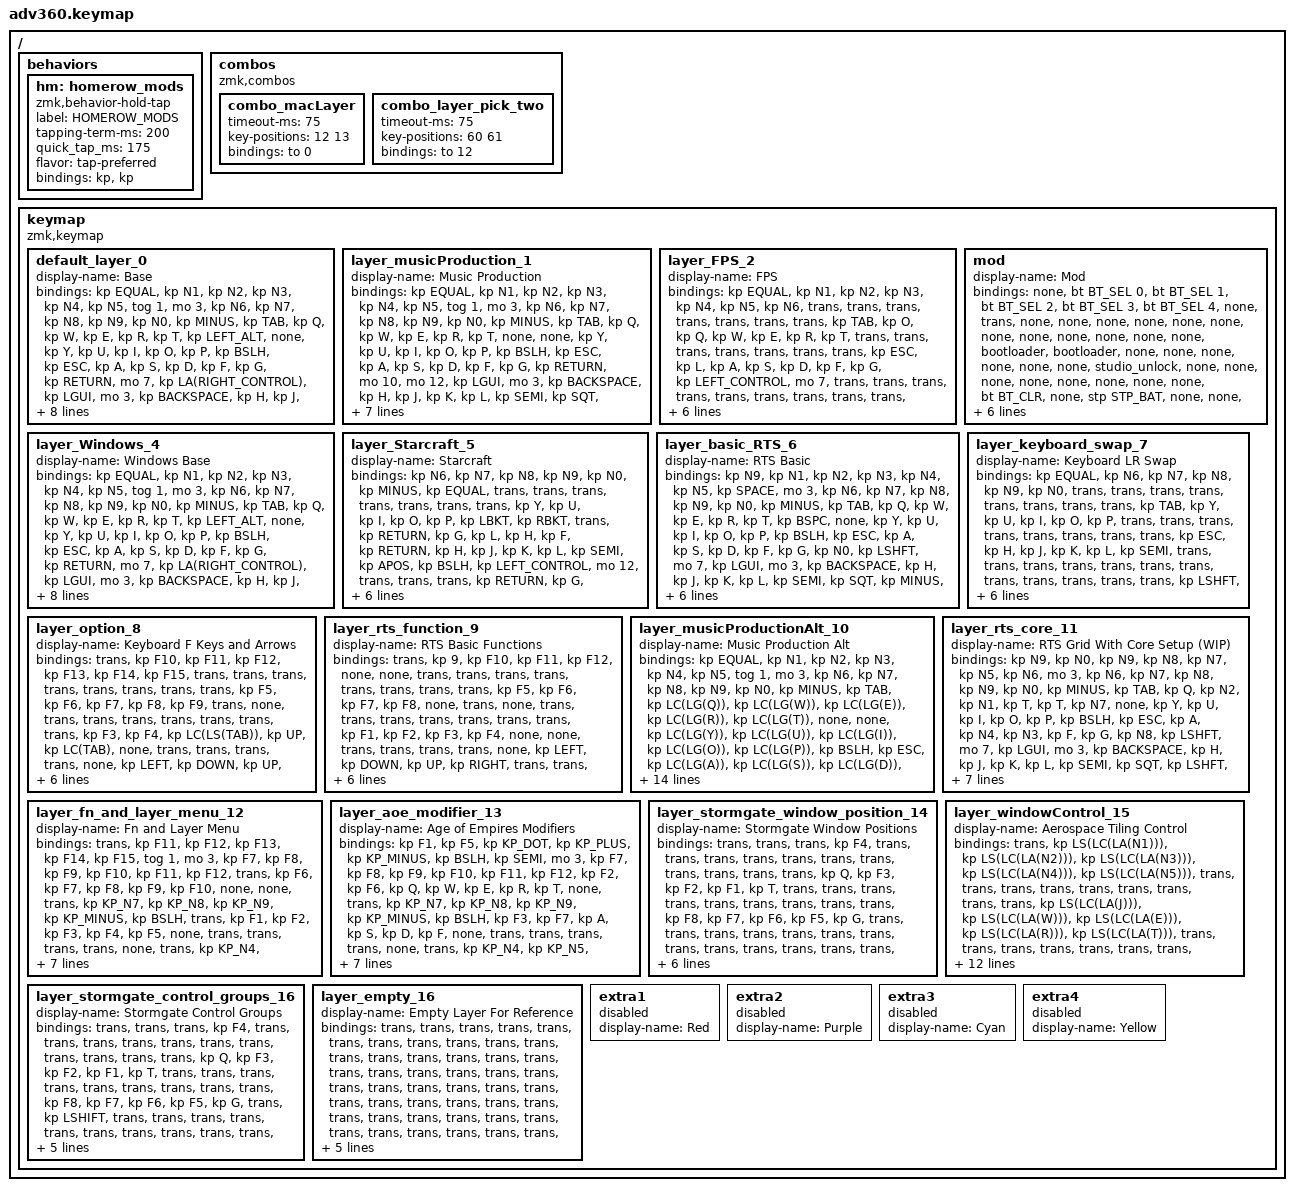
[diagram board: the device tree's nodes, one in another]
#include <behaviors.dtsi>
#include <dt-bindings/zmk/keys.h>
#include <dt-bindings/zmk/bt.h>
#include <dt-bindings/zmk/rgb.h>
#include <dt-bindings/zmk/stp.h>
#include <dt-bindings/zmk/backlight.h>
#include <dt-bindings/zmk/pointing.h>

#define HYPERNOSHIFT LC(LA(LGUI))
#define SEMIHYPER LC(LGUI)

/ {
    behaviors {
      #include "macros.dtsi"
      #include "version.dtsi"

      hm: homerow_mods {
          compatible = "zmk,behavior-hold-tap";
          label = "HOMEROW_MODS";
          #binding-cells = <2>;
          tapping-term-ms = <200>;
          quick_tap_ms = <175>;
          flavor = "tap-preferred";
          bindings = <&kp>, <&kp>;
      };
    };

  combos {
      compatible = "zmk,combos";
      combo_macLayer {
          timeout-ms = <75>;
          key-positions = <12 13>;
          bindings = <&to 0>;
      };
      combo_layer_pick_two {
          timeout-ms = <75>;
          key-positions = <60 61>;
          bindings = <&to 12>;
      };
  };

  keymap {
    compatible = "zmk,keymap";

    default_layer_0 {
      display-name = "Base";
      bindings = <
        &kp EQUAL          &kp N1        &kp N2         &kp N3        &kp N4      &kp N5       &tog 1                                                                                      &mo 3           &kp N6   &kp N7     &kp N8      &kp N9        &kp N0      &kp MINUS
        &kp TAB            &kp Q         &kp W          &kp E         &kp R       &kp T        &kp LEFT_ALT                                                                                &none           &kp Y    &kp U      &kp I       &kp O         &kp P       &kp BSLH
        &kp ESC            &kp A         &kp S          &kp D         &kp F       &kp G        &kp RETURN        &mo 7      &kp LA(RIGHT_CONTROL)            &kp LGUI       &mo 3          &kp BACKSPACE   &kp H    &kp J      &kp K       &kp L         &kp SEMI    &kp SQT
        &kp LSHFT          &kp Z         &kp X          &kp C         &kp V       &kp B                                     &kp LSHFT                        &kp PG_UP                                     &kp N    &kp M      &kp COMMA   &kp DOT       &kp FSLH    &kp RSHFT
        &kp LEFT_ALT       &kp GRAVE     &kp LA(LG(I))  &kp BSPC      &kp SPACE                &kp RIGHT_CONTROL &kp LCMD   &mo 8                            &kp LEFT_ALT   &kp ENTER      &kp SPACE                &kp UP     &kp DOWN    &kp LBKT      &kp RBKT    &sl 4
      >;
    };
    layer_musicProduction_1 {
      display-name = "Music Production";
      bindings = <
        &kp EQUAL          &kp N1        &kp N2         &kp N3        &kp N4      &kp N5             &tog 1                                                                                &mo 3            &kp N6   &kp N7     &kp N8      &kp N9        &kp N0      &kp MINUS
        &kp TAB            &kp Q         &kp W          &kp E         &kp R       &kp T              &none                                                                                 &none            &kp Y    &kp U      &kp I       &kp O         &kp P       &kp BSLH
        &kp ESC            &kp A         &kp S          &kp D         &kp F       &kp G              &kp RETURN          &mo 10       &mo 12                  &kp LGUI       &mo 3         &kp BACKSPACE    &kp H    &kp J      &kp K       &kp L         &kp SEMI    &kp SQT
        &kp LSHFT          &kp Z         &kp X          &kp C         &kp V       &kp B                                  &kp LSHFT               &kp PG_UP                                     &kp N    &kp M      &kp COMMA   &kp DOT       &kp FSLH    &kp RSHFT
        &kp LEFT_ALT       &kp GRAVE     &kp LA(LG(I))  &kp BSPC      &kp BACKSPACE                  &kp RIGHT_CONTROL   &kp LCMD     &mo 8                   &kp LEFT_ALT   &kp ENTER      &kp SPACE                &kp UP     &kp DOWN    &kp LBKT      &kp RBKT    &sl 4
      >;
    };

    layer_FPS_2 {
      display-name = "FPS";
      bindings = <
        &kp EQUAL          &kp N1             &kp N2        &kp N3        &kp N4        &kp N5   &kp N6                                                                        &trans  &trans  &trans  &trans  &trans  &trans  &trans
        &kp TAB            &kp O              &kp Q         &kp W         &kp E         &kp R    &kp T                                                                         &trans  &trans  &trans  &trans  &trans  &trans  &trans
        &kp ESC            &kp L              &kp A         &kp S         &kp D         &kp F    &kp G      &kp LEFT_CONTROL      &mo 7                        &trans  &trans  &trans  &trans  &trans  &trans  &trans  &trans  &trans
        &kp DOT            &kp Z              &kp X         &kp C         &kp V         &kp B                                     &kp SEMI                                     &trans  &trans  &trans  &trans  &trans  &trans  &trans
        &kp LEFT_ALT       &kp GRAV           &kp FSLH      &kp ENTER     &kp LEFT_ALT           &kp LSHIFT &kp SPACE             &mo 12                       &trans  &trans  &trans          &trans  &trans  &trans  &trans  &trans
      >;
    };

    mod {
      display-name = "Mod";
      bindings = <
        &none &bt BT_SEL 0 &bt BT_SEL 1 &bt BT_SEL 2 &bt BT_SEL 3 &bt BT_SEL 4 &none                                                                     &trans                 &none        &none        &none        &none &none &none
        &none &none        &none        &none        &none        &none        &bootloader                                                               &bootloader            &none        &none        &none        &none &none &none
        &studio_unlock &none        &none        &none        &none        &none        &none                   &none &none &bt BT_CLR &none                      &stp STP_BAT &none        &none        &none        &none &none &none
        &none &none        &none        &none        &macro_ver   &none                                      &none &none                                                        &none        &none        &none        &none &none &none
        &none &none        &none        &none        &none                                       &none &none &none &none      &bl BL_TOG &rgb_ug RGB_TOG                                     &bl BL_INC   &bl BL_DEC   &none &none &none
      >;
    };

    layer_Windows_4 {
      display-name = "Windows Base";
      bindings = <
        &kp EQUAL          &kp N1        &kp N2         &kp N3        &kp N4      &kp N5       &tog 1                                                                                            &mo 3           &kp N6   &kp N7     &kp N8      &kp N9        &kp N0      &kp MINUS
        &kp TAB            &kp Q         &kp W          &kp E         &kp R       &kp T        &kp LEFT_ALT                                                                                      &none           &kp Y    &kp U      &kp I       &kp O         &kp P       &kp BSLH
        &kp ESC            &kp A         &kp S          &kp D         &kp F       &kp G        &kp RETURN        &mo 7      &kp LA(RIGHT_CONTROL)                  &kp LGUI       &mo 3          &kp BACKSPACE   &kp H    &kp J      &kp K       &kp L         &kp SEMI    &kp SQT
        &kp LSHFT          &kp Z         &kp X          &kp C         &kp V       &kp B                                     &kp LSHFT                              &kp PG_UP                                     &kp N    &kp M      &kp COMMA   &kp DOT       &kp FSLH    &kp RSHFT
        &kp LCMD           &kp GRAVE     &kp LS(LC(I))  &kp BSPC      &kp SPACE                &kp LEFT_ALT      &kp LEFT_CONTROL   &mo 8                                  &kp LEFT_ALT   &kp ENTER      &kp SPACE                &kp UP     &kp DOWN    &kp LBKT      &kp RBKT    &sl 4
        >;
    };

    layer_Starcraft_5 {
      display-name = "Starcraft";
      bindings = <
        &kp N6   &kp N7     &kp N8     &kp N9   &kp N0    &kp MINUS    &kp EQUAL                                                              &trans       &trans       &trans   &trans   &trans  &trans  &trans
        &kp Y    &kp U      &kp I      &kp O    &kp P     &kp LBKT     &kp RBKT                                                               &trans       &kp RETURN   &kp G    &kp L    &kp H   &kp F   &kp RETURN
        &kp H    &kp J      &kp K      &kp L    &kp SEMI  &kp APOS     &kp BSLH    &kp LEFT_CONTROL  &mo 12                   &trans  &trans  &trans       &kp RETURN   &kp G    &kp ESC  &kp W   &trans  &trans   
        &kp N    &kp M      &kp COMMA  &kp DOT  &kp FSLH  &kp G                                      &trans                   &trans                       &trans       &trans   &trans   &trans  &trans  &trans
        &kp TAB  &kp GRAVE  &kp T      &kp V    &kp B                  &kp RSHFT   &kp LEFT_ALT      &trans                   &trans  &trans  &trans                    &trans   &trans   &trans  &trans  &to 0
      >;
    };

    layer_basic_RTS_6 {
      display-name = "RTS Basic";
      bindings = <
        &kp N9             &kp N1        &kp N2         &kp N3        &kp N4      &kp N5       &kp SPACE                                                                                         &mo 3           &kp N6   &kp N7     &kp N8      &kp N9        &kp N0      &kp MINUS
        &kp TAB            &kp Q         &kp W          &kp E         &kp R       &kp T        &kp BSPC                                                                                          &none           &kp Y    &kp U      &kp I       &kp O         &kp P       &kp BSLH
        &kp ESC            &kp A         &kp S          &kp D         &kp F       &kp G        &kp N0            &kp LSHFT  &mo 7                                  &kp LGUI       &mo 3          &kp BACKSPACE   &kp H    &kp J      &kp K       &kp L         &kp SEMI    &kp SQT
        &kp MINUS          &kp Z         &kp X          &kp C         &kp V       &kp B                                     &kp SPACE                              &kp PG_UP                                     &kp N    &kp M      &kp COMMA   &kp DOT       &kp FSLH    &kp RSHFT
        &kp BSLH           &kp GRAVE     &kp N6         &kp N7        &kp N8               &kp LEFT_ALT      &kp LEFT_CONTROL   &mo 9                          &kp LEFT_ALT   &kp ENTER      &kp SPACE                &kp UP     &kp DOWN    &kp LBKT      &kp RBKT    &sl 4
      >;
    };
    
    layer_keyboard_swap_7 {
      display-name = "Keyboard LR Swap";
      bindings = <
        &kp EQUAL    &kp N6   &kp N7     &kp N8      &kp N9        &kp N0      &trans                                                                  &trans  &trans  &trans  &trans  &trans  &trans  &trans
        &kp TAB      &kp Y    &kp U      &kp I       &kp O         &kp P       &trans                                                                  &trans  &trans  &trans  &trans  &trans  &trans  &trans
        &kp ESC      &kp H    &kp J      &kp K       &kp L         &kp SEMI    &trans            &trans    &trans                      &trans  &trans  &trans  &trans  &trans  &trans  &trans  &trans  &trans
        &kp LSHFT    &kp N    &kp M      &kp COMMA   &kp DOT       &kp FSLH                                &kp LSHFT                   &trans                  &trans  &trans  &trans  &trans  &trans  &trans
        &kp LEFT_ALT &none    &none      &none       &none                     &kp RIGHT_CONTROL &kp LCMD  &trans                      &trans  &trans  &trans          &trans  &trans  &trans  &trans  &trans
      >;
    };

    layer_option_8 {
      display-name = "Keyboard F Keys and Arrows";
      bindings = <
        &trans       &kp F10    &kp F11      &kp F12                &kp F13      &kp F14                &kp F15                                                                   &trans        &trans        &trans       &trans         &trans         &trans           &trans
        &trans       &kp F5     &kp F6       &kp F7                 &kp F8       &kp F9                 &trans                                                                    &none         &trans        &trans       &trans         &trans         &trans           &trans
        &trans       &kp F3     &kp F4       &kp LC(LS(TAB))        &kp UP       &kp LC(TAB)            &none      &trans     &trans                       &trans     &trans      &none         &kp LEFT      &kp DOWN     &kp UP         &kp RIGHT      &trans           &trans
        &trans       &kp F1     &kp F2       &kp LEFT               &kp DOWN     &kp RIGHT                                    &mo 12                       &trans                               &trans        &trans       &trans         &trans         &trans           &trans
        &mo 12        &trans     &trans       &kp LEFT_ALT          &mo 9                               &trans     &trans     &trans                       &trans     &trans      &trans                   &trans       &trans         &trans         &trans           &mo 12
      >;
    };

    layer_rts_function_9 {
      display-name = "RTS Basic Functions";
      bindings = <
        &trans       &kp 9      &kp F10      &kp F11                &kp F12      &none                  &none                                                                                       &trans        &trans        &trans       &trans         &trans         &trans           &trans
        &trans       &kp F5     &kp F6       &kp F7                 &kp F8       &none                  &trans                                                                                      &none         &trans        &trans       &trans         &trans         &trans           &trans
        &trans       &kp F1     &kp F2       &kp F3                 &kp F4       &none                  &none             &trans                &trans                       &trans     &trans      &none         &kp LEFT      &kp DOWN     &kp UP         &kp RIGHT      &trans           &trans
        &trans       &none      &none        &none                  &none        &none                                                          &kp LSHFT                    &trans                               &trans        &trans       &trans         &trans         &trans           &trans
        &none        &trans     &trans       &none                  &none                               &kp LEFT_ALT      &kp LEFT_CONTROL      &trans                       &trans     &trans      &trans                      &trans       &trans         &trans         &trans           &mo 12
        >;
    };

    layer_musicProductionAlt_10 {
      display-name = "Music Production Alt";
      bindings = <
        &kp EQUAL          &kp N1                  &kp N2                  &kp N3                  &kp N4                     &kp N5           &tog 1                                                                                             &mo 3           &kp N6            &kp N7              &kp N8               &kp N9          &kp N0             &kp MINUS
        &kp TAB            &kp LC(LG(Q))           &kp LC(LG(W))           &kp LC(LG(E))           &kp LC(LG(R))              &kp LC(LG(T))    &none                                                                                              &none           &kp LC(LG(Y))     &kp LC(LG(U))       &kp LC(LG(I))        &kp LC(LG(O))   &kp LC(LG(P))      &kp BSLH
        &kp ESC            &kp LC(LG(A))           &kp LC(LG(S))           &kp LC(LG(D))           &kp LC(LG(F))              &kp LC(LG(G))    &kp RETURN  &kp SEMIHYPER      &mo 12                                &kp LGUI       &mo 3          &kp BACKSPACE   &kp LC(LG(H))     &kp LC(LG(J))       &kp LC(LG(K))        &kp LC(LG(L))   &kp SEMI           &kp SQT
        &kp LSHFT          &kp LS(LC(LA(LG(Z))))   &kp LS(LC(LA(LG(X))))   &kp LS(LC(LA(LG(C))))   &kp LS(LC(LA(LG(V))))      &kp LC(LG(B))                                   &kp HYPERNOSHIFT                      &kp PG_UP                                     &kp LC(LG(N))     &kp LC(LG(M))       &kp COMMA            &kp DOT         &kp FSLH           &kp RSHFT
        &kp RIGHT_CONTROL  &kp GRAVE               &kp LA(LG(I))           &kp LEFT_ALT            &kp LC(LG(BACKSPACE))                       &kp SPACE   &kp LCMD           &mo 8                                 &kp LEFT_ALT   &kp ENTER      &kp SPACE                         &kp UP              &kp DOWN             &kp LBKT        &kp RBKT           &sl 4
      >;
    };

    layer_rts_core_11 {
      display-name = "RTS Grid With Core Setup (WIP)";
      bindings = <
        &kp N9             &kp N0        &kp N9         &kp N8        &kp N7      &kp N5       &kp N6                                                                                          &mo 3           &kp N6   &kp N7     &kp N8      &kp N9        &kp N0      &kp MINUS
        &kp TAB            &kp Q         &kp N2         &kp N1        &kp T       &kp T        &kp N7                                                                                          &none           &kp Y    &kp U      &kp I       &kp O         &kp P       &kp BSLH
        &kp ESC            &kp A         &kp N4         &kp N3        &kp F       &kp G        &kp N8          &kp LSHFT          &mo 7                          &kp LGUI       &mo 3          &kp BACKSPACE   &kp H    &kp J      &kp K       &kp L         &kp SEMI    &kp SQT
        &kp LSHFT          &kp Z         &kp N6         &kp N5        &kp V       &kp B                                           &kp LSHFT                      &kp PG_UP                                     &kp N    &kp M      &kp COMMA   &kp DOT       &kp FSLH    &kp RSHFT
        &kp LCMD           &kp GRAVE     &kp N0         &kp BSPC      &kp SPACE                &kp LEFT_ALT    &kp LEFT_CONTROL   &mo 9                          &kp LEFT_ALT   &kp ENTER      &kp SPACE                &kp UP     &kp DOWN    &kp LBKT      &kp RBKT    &sl 4
      >;
    };

    layer_fn_and_layer_menu_12 {
      display-name = "Fn and Layer Menu";
      bindings = <
        &trans  &kp F11  &kp F12  &kp F13  &kp F14  &kp F15            &tog 1                                                   &mo 3   &kp F7  &kp F8        &kp F9         &kp F10         &kp F11        &kp F12
        &trans  &kp F6   &kp F7   &kp F8   &kp F9   &kp F10            &none                                                    &none   &trans  &kp KP_N7     &kp KP_N8      &kp KP_N9       &kp KP_MINUS   &kp BSLH
        &trans  &kp F1   &kp F2   &kp F3   &kp F4   &kp F5             &none   &trans  &trans                   &trans  &trans  &none   &trans  &kp KP_N4     &kp KP_N5      &kp KP_N6       &kp KP_PLUS    &kp SQT
        &trans  &to 0    &to 4    &to 2    &to 5    &to 1                              &trans                   &trans                  &trans  &kp KP_N1     &kp KP_N2      &kp KP_N3       &kp KP_ENTER   &kp RSHFT
        &trans  &to 6    &to 11   &trans   &trans                      &trans  &trans  &trans                   &trans  &trans  &trans          &kp KP_N0     &kp KP_N0      &kp KP_DOT      &kp RBKT       &trans
      >;
    };

    layer_aoe_modifier_13 {
      display-name = "Age of Empires Modifiers";
      bindings = <
        &kp F1   &kp F5   &kp KP_DOT   &kp KP_PLUS   &kp KP_MINUS   &kp BSLH   &kp SEMI                                                 &mo 3   &kp F7  &kp F8        &kp F9         &kp F10         &kp F11        &kp F12
        &kp F2   &kp F6   &kp Q        &kp W         &kp E          &kp R      &kp T                                                    &none   &trans  &kp KP_N7     &kp KP_N8      &kp KP_N9       &kp KP_MINUS   &kp BSLH
        &kp F3   &kp F7   &kp A        &kp S         &kp D          &kp F      &none   &trans  &trans                   &trans  &trans  &none   &trans  &kp KP_N4     &kp KP_N5      &kp KP_N6       &kp KP_PLUS    &kp SQT
        &kp F4   &kp F8   &kp Z        &kp X         &kp C          &kp V                      &trans                   &trans                  &trans  &kp KP_N1     &kp KP_N2      &kp KP_N3       &kp KP_ENTER   &kp RSHFT
        &kp F5   &kp F9   &kp Z        &kp X         &kp C                     &trans  &trans  &trans                   &trans  &trans  &trans          &kp KP_N0     &kp KP_N0      &kp KP_DOT      &kp RBKT       &trans
      >;
    };

    layer_stormgate_window_position_14 {
      display-name = "Stormgate Window Positions";
      bindings = <
        &trans  &trans        &trans         &kp F4        &trans      &trans          &trans                                                      &trans  &trans  &trans  &trans  &trans  &trans  &trans
        &trans  &kp Q         &kp F3         &kp F2        &kp F1      &kp T           &trans                                                      &trans  &trans  &trans  &trans  &trans  &trans  &trans
        &trans  &kp F8        &kp F7         &kp F6        &kp F5      &kp G           &trans  &trans  &trans                      &trans  &trans  &trans  &trans  &trans  &trans  &trans  &trans  &trans
        &trans  &kp Z         &kp X          &kp C         &kp V       &kp B                           &kp LEFT_CONTROL            &trans                  &trans  &trans  &trans  &trans  &trans  &trans
        &trans  &trans        &trans         &trans        &trans                      &trans  &trans  &trans                      &trans  &trans  &trans          &trans  &trans  &trans  &trans  &trans
      >;
    };

    layer_windowControl_15 {
      display-name = "Aerospace Tiling Control";
      bindings = <
        &trans  &kp LS(LC(LA(N1)))  &kp LS(LC(LA(N2)))  &kp LS(LC(LA(N3)))  &kp LS(LC(LA(N4)))  &kp LS(LC(LA(N5)))  &trans                                                   &trans  &trans  &trans  &trans  &trans  &trans  &trans
        &trans  &kp LS(LC(LA(J)))   &kp LS(LC(LA(W)))   &kp LS(LC(LA(E)))   &kp LS(LC(LA(R)))   &kp LS(LC(LA(T)))   &trans                                                   &trans  &trans  &trans  &trans  &trans  &trans  &trans
        &trans  &kp LS(LC(LA(A)))   &kp LS(LC(LA(S)))   &kp LS(LC(LA(D)))   &kp LS(LC(LA(F)))   &kp LS(LC(LA(G)))   &trans  &trans  &trans                   &trans  &trans  &trans  &trans  &trans  &trans  &trans  &trans  &trans
        &trans  &kp LS(LC(LA(Z)))   &kp LS(LC(LA(X)))   &kp LS(LC(LA(C)))   &kp LS(LC(LA(V)))   &kp LS(LC(LA(B)))                   &trans                   &trans                  &trans  &trans  &trans  &trans  &trans  &trans
        &trans  &trans              &trans              &trans              &trans                                  &trans  &trans  &trans                   &trans  &trans  &trans          &trans  &trans  &trans  &trans  &trans
      >;
    };

    layer_stormgate_control_groups_16 {
      display-name = "Stormgate Control Groups";
      bindings = <
        &trans  &trans        &trans         &kp F4        &trans      &trans          &trans                                                     &trans  &trans  &trans  &trans  &trans  &trans  &trans
        &trans  &kp Q         &kp F3         &kp F2        &kp F1      &kp T           &trans                                                     &trans  &trans  &trans  &trans  &trans  &trans  &trans
        &trans  &kp F8        &kp F7         &kp F6        &kp F5      &kp G           &trans  &kp LSHIFT  &trans                 &trans  &trans  &trans  &trans  &trans  &trans  &trans  &trans  &trans
        &trans  &kp Z         &kp X          &kp C         &kp V       &kp B                               &trans                 &trans                  &trans  &trans  &trans  &trans  &trans  &trans
        &trans  &trans        &trans         &trans        &trans                      &trans  &trans  &trans                     &trans  &trans  &trans          &trans  &trans  &trans  &trans  &trans
      >;
    };
    layer_empty_16 {
      display-name = "Empty Layer For Reference";
      bindings = <
        &trans  &trans  &trans  &trans  &trans  &trans            &trans                                                     &trans  &trans  &trans  &trans  &trans  &trans  &trans
        &trans  &trans  &trans  &trans  &trans  &trans            &trans                                                     &trans  &trans  &trans  &trans  &trans  &trans  &trans
        &trans  &trans  &trans  &trans  &trans  &trans            &trans  &trans  &trans                     &trans  &trans  &trans  &trans  &trans  &trans  &trans  &trans  &trans
        &trans  &trans  &trans  &trans  &trans  &trans                            &trans                     &trans                  &trans  &trans  &trans  &trans  &trans  &trans
        &trans  &trans  &trans  &trans  &trans                    &trans  &trans  &trans                     &trans  &trans  &trans          &trans  &trans  &trans  &trans  &trans
      >;
    };
    extra1 { 
      display-name = "Red";    
      status = "reserved";
    };

    extra2 { 
      display-name = "Purple";    
      status = "reserved";
    };

    extra3 { 
      display-name = "Cyan";    
      status = "reserved";
    };

    extra4 { 
      display-name = "Yellow";    
      status = "reserved";
    };
  };
};
